# EFM32GG11B420F2048IL112 register map
File version: 4.0.0
CPU: CM4 r0p1, little endian, MPU, FPU, 3 interrupt priority bits
Registers are 32-bit, read-write, reset 0x0 unless marked. A register's access mark holds for its fields unless they carry their own. Offsets are from the block's base; [hi:lo] are bit positions; {n}, {i} and the like mark numbered series; 'fields as' and 'values as' point back to an identical list.

## ACMP0
Base 0x40080000
Same registers: ACMP1 0x40080400, ACMP2 0x40080800, ACMP3 0x40080C00
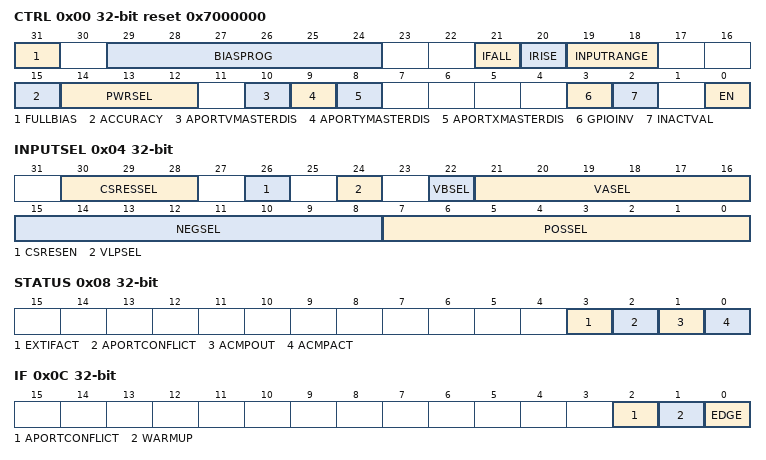
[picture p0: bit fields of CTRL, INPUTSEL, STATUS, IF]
0x00 CTRL reset 0x7000000 — Control Register
  [31] FULLBIAS — Full Bias Current
  [29:24] BIASPROG — Bias Configuration
  [21] IFALL — Falling Edge Interrupt Sense
  [20] IRISE — Rising Edge Interrupt Sense
  [19:18] INPUTRANGE
    0=FULL (Setting when the input can be from 0 to ACMPVDD.); 1=GTVDDDIV2 (Setting when the input will always be greater than ACMPVDD/2.); 2=LTVDDDIV2 (Setting when the input will always be less than ACMPVDD/2.)
  [15] ACCURACY — ACMP Accuracy Mode
  [14:12] PWRSEL — Power Select
    0=AVDD (AVDD supply); 1=DVDD (DVDD supply); 2=IOVDD0 (IOVDD/IOVDD0 supply); 4=IOVDD1 (IOVDD1 supply (if part has two I/O voltages))
  [10] APORTVMASTERDIS — APORT Bus Master Disable for Bus Selected By VASEL
  [9] APORTYMASTERDIS — APORT Bus Y Master Disable
  [8] APORTXMASTERDIS — APORT Bus X Master Disable
  [3] GPIOINV — Comparator GPIO Output Invert
  [2] INACTVAL — Inactive Value
  [0] EN — Analog Comparator Enable
0x04 INPUTSEL — Input Selection Register
  [30:28] CSRESSEL — Capacitive Sense Mode Internal Resistor Select
    {v}=RES{v} (Internal capacitive sense resistor value {v}) (v=0..7)
  [26] CSRESEN — Capacitive Sense Mode Internal Resistor Enable
  [24] VLPSEL — Low-Power Sampled Voltage Selection
  [22] VBSEL — VB Selection
  [21:16] VASEL — VA Selection
    0=VDD (ACMPVDD); 1=APORT2YCH0 (APORT2Y Channel 0); 3=APORT2YCH2 (APORT2Y Channel 2); 5=APORT2YCH4 (APORT2Y Channel 4); 7=APORT2YCH6 (APORT2Y Channel 6); 9=APORT2YCH8 (APORT2Y Channel 8); 11=APORT2YCH10 (APORT2Y Channel 10); 13=APORT2YCH12 (APORT2Y Channel 12); 15=APORT2YCH14 (APORT2Y Channel 14); 17=APORT2YCH16 (APORT2Y Channel 16); 19=APORT2YCH18 (APORT2Y Channel 18); 21=APORT2YCH20 (APORT2Y Channel 20); 23=APORT2YCH22 (APORT2Y Channel 22); 25=APORT2YCH24 (APORT2Y Channel 24); 27=APORT2YCH26 (APORT2Y Channel 26); 29=APORT2YCH28 (APORT2Y Channel 28); 31=APORT2YCH30 (APORT2Y Channel 30); 32=APORT1XCH0 (APORT1X Channel 0); 33=APORT1YCH1 (APORT1Y Channel 1); 34=APORT1XCH2 (APORT1X Channel 2); 35=APORT1YCH3 (APORT1Y Channel 3); 36=APORT1XCH4 (APORT1X Channel 4); 37=APORT1YCH5 (APORT1Y Channel 5); 38=APORT1XCH6 (APORT1X Channel 6); 39=APORT1YCH7 (APORT1Y Channel 7); 40=APORT1XCH8 (APORT1X Channel 8); 41=APORT1YCH9 (APORT1Y Channel 9); 42=APORT1XCH10 (APORT1X Channel 10); 43=APORT1YCH11 (APORT1Y Channel 11); 44=APORT1XCH12 (APORT1X Channel 12); 45=APORT1YCH13 (APORT1Y Channel 13); 46=APORT1XCH14 (APORT1X Channel 14); 47=APORT1YCH15 (APORT1Y Channel 15); 48=APORT1XCH16 (APORT1X Channel 16); 49=APORT1YCH17 (APORT1Y Channel 17); 50=APORT1XCH18 (APORT1X Channel 18); 51=APORT1YCH19 (APORT1Y Channel 19); 52=APORT1XCH20 (APORT1X Channel 20); 53=APORT1YCH21 (APORT1Y Channel 21); 54=APORT1XCH22 (APORT1X Channel 22); 55=APORT1YCH23 (APORT1Y Channel 23); 56=APORT1XCH24 (APORT1X Channel 24); 57=APORT1YCH25 (APORT1Y Channel 25); 58=APORT1XCH26 (APORT1X Channel 26); 59=APORT1YCH27 (APORT1Y Channel 27); 60=APORT1XCH28 (APORT1X Channel 28); 61=APORT1YCH29 (APORT1Y Channel 29); 62=APORT1XCH30 (APORT1X Channel 30); 63=APORT1YCH31 (APORT1Y Channel 31)
  [15:8] NEGSEL — Negative Input Select
  [7:0] POSSEL — Positive Input Select
0x08 STATUS ro
  [3] EXTIFACT — External Override Interface Active
  [2] APORTCONFLICT — APORT Conflict Output
  [1] ACMPOUT — Analog Comparator Output
  [0] ACMPACT — Analog Comparator Active
0x0C IF ro — Interrupt Flag Register
  [2] APORTCONFLICT — APORT Conflict Interrupt Flag
  [1] WARMUP — Warm-up Interrupt Flag
  [0] EDGE — Edge Triggered Interrupt Flag
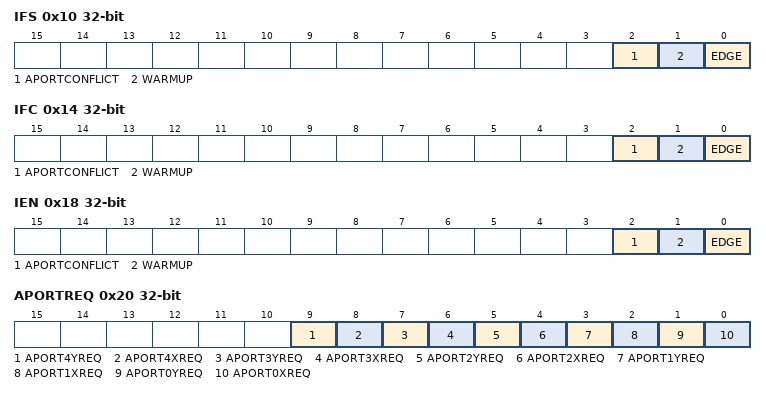
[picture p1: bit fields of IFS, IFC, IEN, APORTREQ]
0x10 IFS wo — Interrupt Flag Set Register
  [2] APORTCONFLICT — Set APORTCONFLICT Interrupt Flag
  [1] WARMUP — Set WARMUP Interrupt Flag
  [0] EDGE — Set EDGE Interrupt Flag
0x14 IFC wo — Interrupt Flag Clear Register
  [2] APORTCONFLICT — Clear APORTCONFLICT Interrupt Flag
  [1] WARMUP — Clear WARMUP Interrupt Flag
  [0] EDGE — Clear EDGE Interrupt Flag
0x18 IEN — Interrupt Enable Register
  [2] APORTCONFLICT — APORTCONFLICT Interrupt Enable
  [1] WARMUP — WARMUP Interrupt Enable
  [0] EDGE — EDGE Interrupt Enable
0x20 APORTREQ ro — APORT Request Status Register
  [9] APORT4YREQ — 1 If the Bus Connected to APORT4Y is Requested
  [8] APORT4XREQ — 1 If the Bus Connected to APORT4X is Requested
  [7] APORT3YREQ — 1 If the Bus Connected to APORT3Y is Requested
  [6] APORT3XREQ — 1 If the Bus Connected to APORT3X is Requested
  [5] APORT2YREQ — 1 If the Bus Connected to APORT2Y is Requested
  [4] APORT2XREQ — 1 If the Bus Connected to APORT2X is Requested
  [3] APORT1YREQ — 1 If the Bus Connected to APORT1X is Requested
  [2] APORT1XREQ — 1 If the Bus Connected to APORT2X is Requested
  [1] APORT0YREQ — 1 If the Bus Connected to APORT0Y is Requested
  [0] APORT0XREQ — 1 If the Bus Connected to APORT0X is Requested
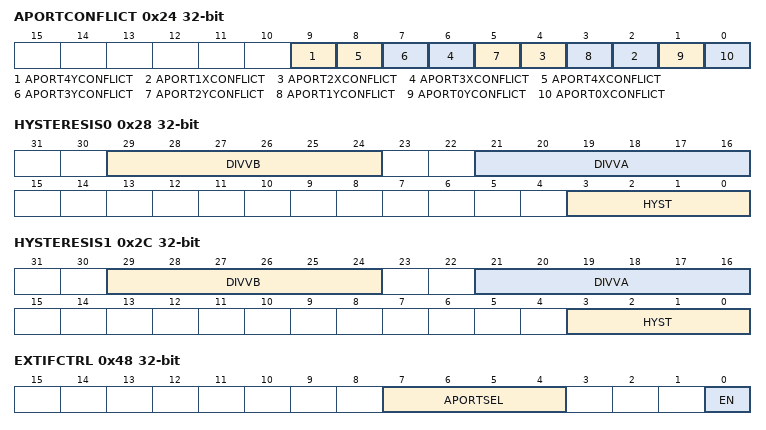
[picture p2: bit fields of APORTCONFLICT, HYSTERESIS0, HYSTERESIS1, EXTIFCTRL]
0x24 APORTCONFLICT ro — APORT Conflict Status Register
  [9] APORT4YCONFLICT — 1 If the Bus Connected to APORT4Y is in Conflict With Another Peripheral
  [2n] APORT{n}XCONFLICT (n=1..4) — 1 If the Bus Connected to APORT{n}X is in Conflict With Another Peripheral
  [7] APORT3YCONFLICT — 1 If the Bus Connected to APORT3Y is in Conflict With Another Peripheral
  [5] APORT2YCONFLICT — 1 If the Bus Connected to APORT2Y is in Conflict With Another Peripheral
  [3] APORT1YCONFLICT — 1 If the Bus Connected to APORT1X is in Conflict With Another Peripheral
  [1] APORT0YCONFLICT — 1 If the Bus Connected to APORT0Y is in Conflict With Another Peripheral
  [0] APORT0XCONFLICT — 1 If the Bus Connected to APORT0X is in Conflict With Another Peripheral
0x28 HYSTERESIS0
  [29:24] DIVVB — Divider for VB Voltage When ACMPOUT=0
  [21:16] DIVVA — Divider for VA Voltage When ACMPOUT=0
  [3:0] HYST — Hysteresis Select When ACMPOUT=0
    0=No hysteresis; 1=14 mV hysteresis; 2=25 mV hysteresis; 3=30 mV hysteresis; 4=35 mV hysteresis; 5=39 mV hysteresis; 6=42 mV hysteresis; 7=45 mV hysteresis; 8=No hysteresis; 9=-14 mV hysteresis; 10=-25 mV hysteresis; 11=-30 mV hysteresis; 12=-35 mV hysteresis; 13=-39 mV hysteresis; 14=-42 mV hysteresis; 15=-45 mV hysteresis
0x2C HYSTERESIS1
  [29:24] DIVVB — Divider for VB Voltage When ACMPOUT=1
  [21:16] DIVVA — Divider for VA Voltage When ACMPOUT=1
  [3:0] HYST — Hysteresis Select When ACMPOUT=1
    values as HYSTERESIS0.HYST
0x40 ROUTEPEN — I/O Routing Pine Enable Register
  [0] OUTPEN — ACMP Output Pin Enable
0x44 ROUTELOC0 — I/O Routing Location Register
  [5:0] OUTLOC — I/O Location
    {v}=LOC{v} (Location {v}) (v=0..7)
0x48 EXTIFCTRL — External Override Interface Control
  [7:4] APORTSEL — APORT Selection for External Interface
    0=APORT0X (APORT0X used. EXT_BASE = ACMP_INPUTSEL_POSSEL_APORT0XCH0.); 1=APORT0Y (APORT0Y used. EXT_BASE = ACMP_INPUTSEL_POSSEL_APORT0YCH0.); 2=APORT1X (APORT1X used. EXT_BASE = ACMP_INPUTSEL_POSSEL_APORT1XCH0.); 3=APORT1Y (APORT1Y used. EXT_BASE = ACMP_INPUTSEL_POSSEL_APORT1XCH0.); 4=APORT1XY (APORT1X/Y used. EXT_BASE = ACMP_INPUTSEL_POSSEL_APORT1XCH0.); 5=APORT2X (APORT2X used. EXT_BASE = ACMP_INPUTSEL_POSSEL_APORT2YCH0.); 6=APORT2Y (APORT2Y used. EXT_BASE = ACMP_INPUTSEL_POSSEL_APORT2YCH0.); 7=APORT2YX (APORT2Y/X used. EXT_BASE = ACMP_INPUTSEL_POSSEL_APORT2YCH0.); 8=APORT3X (APORT3X used. EXT_BASE = ACMP_INPUTSEL_POSSEL_APORT3XCH0.); 9=APORT3Y (APORT3Y used. EXT_BASE = ACMP_INPUTSEL_POSSEL_APORT3XCH0.); 10=APORT3XY (APORT3X/Y used. EXT_BASE = ACMP_INPUTSEL_POSSEL_APORT3XCH0.); 11=APORT4X (APORT4X used. EXT_BASE = ACMP_INPUTSEL_POSSEL_APORT4YCH0.); 12=APORT4Y (APORT4Y used. EXT_BASE = ACMP_INPUTSEL_POSSEL_APORT4YCH0.); 13=APORT4YX (APORT4Y/X used. EXT_BASE = ACMP_INPUTSEL_POSSEL_APORT4YCH0.)
  [0] EN — Enable External Interface
